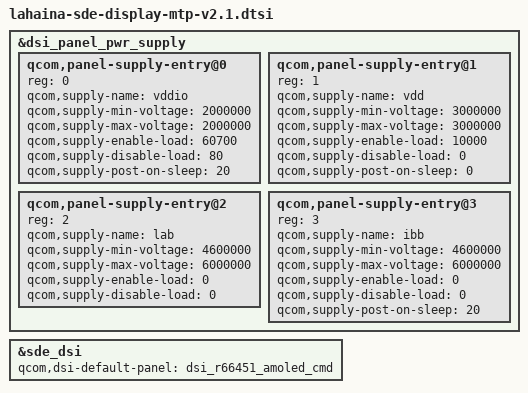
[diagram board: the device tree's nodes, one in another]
&dsi_panel_pwr_supply {
	#address-cells = <1>;
	#size-cells = <0>;

	qcom,panel-supply-entry@0 {
		reg = <0>;
		qcom,supply-name = "vddio";
		qcom,supply-min-voltage = <2000000>;
		qcom,supply-max-voltage = <2000000>;
		qcom,supply-enable-load = <60700>;
		qcom,supply-disable-load = <80>;
		qcom,supply-post-on-sleep = <20>;
	};

	qcom,panel-supply-entry@1 {
		reg = <1>;
		qcom,supply-name = "vdd";
		qcom,supply-min-voltage = <3000000>;
		qcom,supply-max-voltage = <3000000>;
		qcom,supply-enable-load = <10000>;
		qcom,supply-disable-load = <0>;
		qcom,supply-post-on-sleep = <0>;
	};

	qcom,panel-supply-entry@2 {
		reg = <2>;
		qcom,supply-name = "lab";
		qcom,supply-min-voltage = <4600000>;
		qcom,supply-max-voltage = <6000000>;
		qcom,supply-enable-load = <0>;
		qcom,supply-disable-load = <0>;
	};

	qcom,panel-supply-entry@3 {
		reg = <3>;
		qcom,supply-name = "ibb";
		qcom,supply-min-voltage = <4600000>;
		qcom,supply-max-voltage = <6000000>;
		qcom,supply-enable-load = <0>;
		qcom,supply-disable-load = <0>;
		qcom,supply-post-on-sleep = <20>;
	};
};

&sde_dsi {
	qcom,dsi-default-panel = <&dsi_r66451_amoled_cmd>;
};
